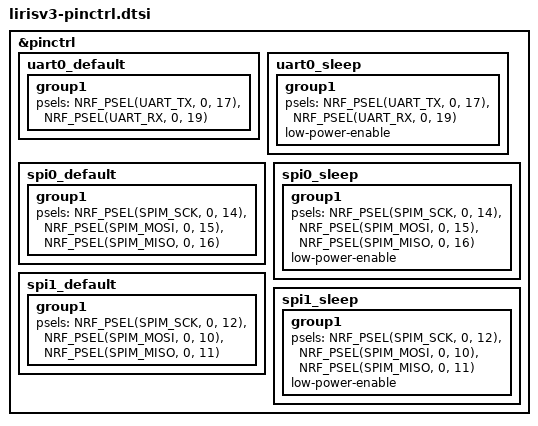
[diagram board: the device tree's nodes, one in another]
/*
 * Copyright (c) 2022 Nordic Semiconductor ASA
 * SPDX-License-Identifier: Apache-2.0
 */

&pinctrl {
	uart0_default: uart0_default {
		group1 {
			psels = <NRF_PSEL(UART_TX, 0, 17)>,
				<NRF_PSEL(UART_RX, 0, 19)>;
		};
	};

	uart0_sleep: uart0_sleep {
		group1 {
			psels = <NRF_PSEL(UART_TX, 0, 17)>,
				<NRF_PSEL(UART_RX, 0, 19)>;
			low-power-enable;
		};
	};

	spi0_default: spi0_default {
		group1 {
			psels = <NRF_PSEL(SPIM_SCK, 0, 14)>,
				<NRF_PSEL(SPIM_MOSI, 0, 15)>,
				<NRF_PSEL(SPIM_MISO, 0, 16)>;
		};
	};

	spi0_sleep: spi0_sleep {
		group1 {
			psels = <NRF_PSEL(SPIM_SCK, 0, 14)>,
				<NRF_PSEL(SPIM_MOSI, 0, 15)>,
				<NRF_PSEL(SPIM_MISO, 0, 16)>;
			low-power-enable;
		};
	};

	spi1_default: spi1_default {
		group1 {
			psels = <NRF_PSEL(SPIM_SCK, 0, 12)>,
				<NRF_PSEL(SPIM_MOSI, 0, 10)>,
				<NRF_PSEL(SPIM_MISO, 0, 11)>;
		};
	};

	spi1_sleep: spi1_sleep {
		group1 {
			psels = <NRF_PSEL(SPIM_SCK, 0, 12)>,
				<NRF_PSEL(SPIM_MOSI, 0, 10)>,
				<NRF_PSEL(SPIM_MISO, 0, 11)>;
			low-power-enable;
		};
	};

};
